# CC23x0 register map
File version: 1.1
CPU: CM0+ r0p4, little endian, no MPU, no FPU, VTOR, 3 interrupt priority bits
Registers are 32-bit, read-write, reset 0x0 unless marked. A register's access mark holds for its fields unless they carry their own. Offsets are from the block's base; [hi:lo] are bit positions; {n}, {i} and the like mark numbered series; 'fields as' and 'values as' point back to an identical list.

## IOC — ULL IOC
Base 0x40003000
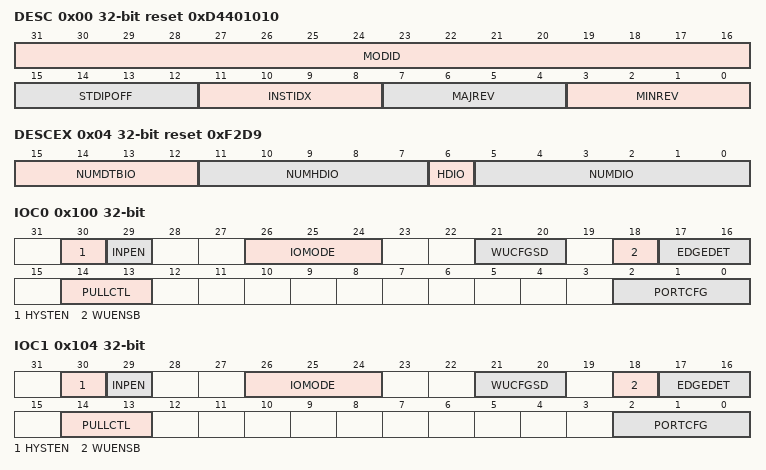
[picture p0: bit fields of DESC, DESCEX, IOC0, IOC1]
0x00 DESC ro reset 0xD4401010 — Description Register. This register provides IP module ID, revision information, instance index and standard MMR registers offset.
  [31:16] MODID — Module identifier used to uniquely identify this IP.
  [15:12] STDIPOFF — Standard IP MMR block offset. Standard IP MMRs are the set of from aggregated IRQ registers till DTB. 0: Standard IP MMRs do not exist 0x1-0xF: Standard IP MMRs begin at offset of (64*STDIPOFF from the base IP address)
  [11:8] INSTIDX — IP Instance ID number. If multiple instances of IP exist in the device, this field can identify the instance number (0-15).
  [7:4] MAJREV — Major revision of IP (0-15).
  [3:0] MINREV — Minor revision of IP (0-15).
0x04 DESCEX ro reset 0xF2D9 — Extended Description Register. This register provides configuration details of the IP to software drivers and end users.
  [15:12] NUMDTBIO — Number of DTB IOs supported. Total DTB IOs supported is NUMDTBIO value +1.
    15=MAXIMUM (Highest possible value); 0=MINIMUM (Smallest value)
  [11:7] NUMHDIO — Number of high drive IOs supported. Total high drive IOs supported is NUMHDIO value +1.
    31=MAXIMUM (Highest possible value); 0=MINIMUM (Smallest value)
  [6] HDIO — High drive IO supported by IOC.
    1=PRESENT (HD IO supported by IOC); 0=ABSENT (HD IO not supported by IOC)
  [5:0] NUMDIO — Number of DIOs supported. Total DIOs supported is NUMDIO value +1.
    63=MAXIMUM (Highest possible value); 0=MINIMUM (Smallest value)
0x100 IOC0 — Configuration of DIO0
  [30] HYSTEN — This field controls input hysteresis
    1=EN (Input hysteresis enabled); 0=DIS (Input hysteresis disabled)
  [29] INPEN — This field controls the input capability of DIO
    1=EN (Input enabled); 0=DIS (Input disabled)
  [26:24] IOMODE — IO Mode. Setting this to value 0x6 or 0x7 will default to normal IO behavior.
    5=OPENS_INV (Open Source, inverted IO); 4=OPENS (Open Source, normal IO); 3=OPEND_INV (Open Drain, inverted IO); 2=OPEND (Open Drain, normal IO); 1=INVERTED (Inverted IO); 0=NORMAL (Normal IO)
  [21:20] WUCFGSD — Wakeup configuration from shutdown
    3=WAKE_HIGH (Wakeup triggered when pad level is high); 2=WAKE_LOW (Wakeup triggered when pad level is low); 1=DIS_1 (Wakeup disabled); 0=DIS_0 (Wakeup disabled)
  [18] WUENSB — Wakeup enable from standby
    1=EN (Wakeup enabled (effective only if EDGEDET is enabled)); 0=DIS (Wakeup disabled)
  [17:16] EDGEDET — Edge detect configuration
    3=EDGE_BOTH (Positive and negative edge detection); 2=EDGE_POS (Positive edge detection); 1=EDGE_NEG (Negative edge detection); 0=EDGE_DIS (No edge detection)
  [14:13] PULLCTL — Pull control. Setting this to value 0x3 disables pull.
    2=PULL_UP (Pull up enabled); 1=PULL_DOWN (Pull down enabled); 0=PULL_DIS (No pull)
  [2:0] PORTCFG — Selects usage of DIO0
    7=DTB (Digital Test Bus function); 6=ANA (Analog function); {v}=PFUNC{v} (Digital peripheral function-{v}) (v=1..5); 0=BASE (Base function)
0x104 IOC1 — Configuration of DIO1
  [30] HYSTEN — This field controls input hysteresis
    values as IOC0.HYSTEN
  [29] INPEN — This field controls the input capability of DIO
    1=EN (Input enabled); 0=DIS (Input disabled)
  [26:24] IOMODE — IO Mode. Setting this to value 0x6 or 0x7 will default to normal IO behavior.
    values as IOC0.IOMODE
  [21:20] WUCFGSD — Wakeup configuration from shutdown
    values as IOC0.WUCFGSD
  [18] WUENSB — Wakeup enable from standby
    values as IOC0.WUENSB
  [17:16] EDGEDET — Edge detect configuration
    values as IOC0.EDGEDET
  [14:13] PULLCTL — Pull control. Setting this to value 0x3 disables pull.
    values as IOC0.PULLCTL
  [2:0] PORTCFG — Selects usage of DIO1
    values as IOC0.PORTCFG
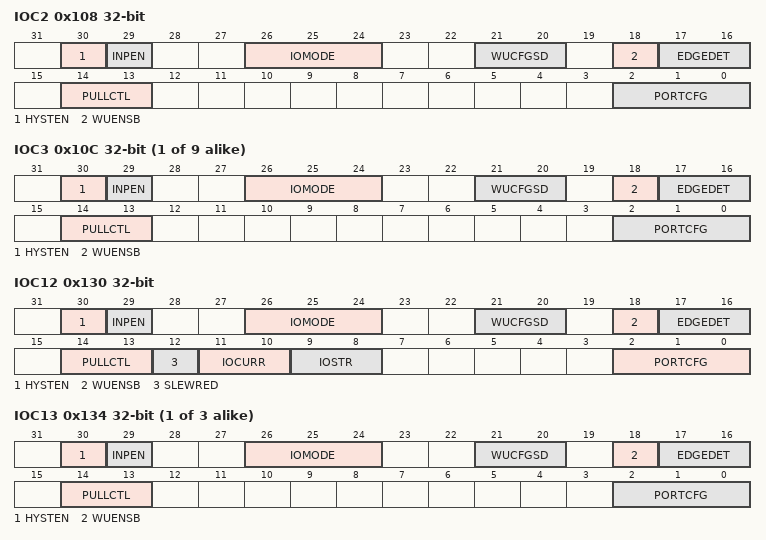
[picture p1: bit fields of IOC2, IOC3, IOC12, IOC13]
0x108 IOC2 — Selects usage of DIO2
  [30] HYSTEN — This field controls input hysteresis
    values as IOC0.HYSTEN
  [29] INPEN — This field controls the input capability of DIO
    1=EN (Input enabled); 0=DIS (Input disabled)
  [26:24] IOMODE — IO Mode. Setting this to value 0x6 or 0x7 will default to normal IO behavior.
    values as IOC0.IOMODE
  [21:20] WUCFGSD — Wakeup configuration from shutdown
    values as IOC0.WUCFGSD
  [18] WUENSB — Wakeup enable from standby
    values as IOC0.WUENSB
  [17:16] EDGEDET — Edge detect configuration
    values as IOC0.EDGEDET
  [14:13] PULLCTL — Pull control. Setting this to value 0x3 disables pull.
    values as IOC0.PULLCTL
  [2:0] PORTCFG — Selects usage of DIO2
    values as IOC0.PORTCFG
{0x100+4i} IOC{i} (i=3..11) — Configuration of DIO{i}
  [30] HYSTEN — This field controls input hysteresis
    values as IOC0.HYSTEN
  [29] INPEN — This field controls the input capability of DIO
    1=EN (Input enabled); 0=DIS (Input disabled)
  [26:24] IOMODE — IO Mode. Setting this to value 0x6 or 0x7 will default to normal IO behavior.
    values as IOC0.IOMODE
  [21:20] WUCFGSD — Wakeup configuration from shutdown
    values as IOC0.WUCFGSD
  [18] WUENSB — Wakeup enable from standby
    values as IOC0.WUENSB
  [17:16] EDGEDET — Edge detect configuration
    values as IOC0.EDGEDET
  [14:13] PULLCTL — Pull control. Setting this to value 0x3 disables pull.
    values as IOC0.PULLCTL
  [2:0] PORTCFG — Selects usage of DIO{i}
    values as IOC0.PORTCFG
0x130 IOC12 — Configuration of DIO12
  [30] HYSTEN — This field controls input hysteresis
    values as IOC0.HYSTEN
  [29] INPEN — This field controls the input capability of DIO
    1=EN (Input enabled); 0=DIS (Input disabled)
  [26:24] IOMODE — IO Mode. Setting this to value 0x6 or 0x7 will default to normal IO behavior.
    values as IOC0.IOMODE
  [21:20] WUCFGSD — Wakeup configuration from shutdown
    values as IOC0.WUCFGSD
  [18] WUENSB — Wakeup enable from standby
    values as IOC0.WUENSB
  [17:16] EDGEDET — Edge detect configuration
    values as IOC0.EDGEDET
  [14:13] PULLCTL — Pull control. Setting this to value 0x3 disables pull.
    values as IOC0.PULLCTL
  [12] SLEWRED — Slew rate configuration
    1=REDUCED (Reduced slew rate); 0=NORMAL (Normal slew rate)
  [11:10] IOCURR — Output current configuration. Writing value 0x3 defaults to 2mA current setting.
    2=CUR_8MA (8mA); 1=CUR_4MA (4mA); 0=CUR_2MA (2mA)
  [9:8] IOSTR — Drive strength configuration
    3=MAX (Maximum drive strength); 2=MEDIUM (Medium drive strength); 1=MIN (Minimum drive stregnth); 0=AUTO (Automatic drive strength adjustment)
  [2:0] PORTCFG — Selects usage of DIO12
    values as IOC0.PORTCFG
{0x100+4i} IOC{i} (i=13..15) — Configuration of DIO{i}
  fields as IOC3
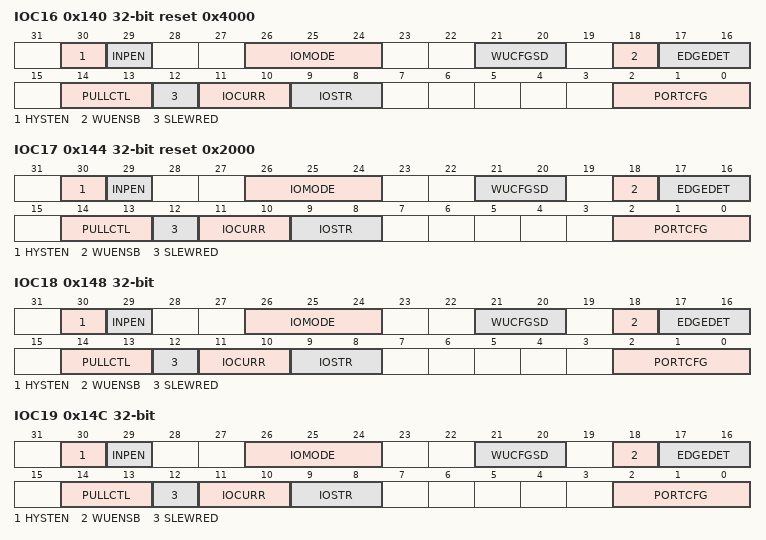
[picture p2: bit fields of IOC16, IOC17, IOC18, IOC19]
0x140 IOC16 reset 0x4000 — Configuration of DIO16
  [30] HYSTEN — This field controls input hysteresis
    values as IOC0.HYSTEN
  [29] INPEN — This field controls the input capability of DIO
    1=EN (Input enabled); 0=DIS (Input disabled)
  [26:24] IOMODE — IO Mode. Setting this to value 0x6 or 0x7 will default to normal IO behavior.
    values as IOC0.IOMODE
  [21:20] WUCFGSD — Wakeup configuration from shutdown
    values as IOC0.WUCFGSD
  [18] WUENSB — Wakeup enable from standby
    values as IOC0.WUENSB
  [17:16] EDGEDET — Edge detect configuration
    values as IOC0.EDGEDET
  [14:13] PULLCTL — Pull control. Setting this to value 0x3 disables pull.
    values as IOC0.PULLCTL
  [12] SLEWRED — Slew rate configuration
    1=REDUCED (Reduced slew rate); 0=NORMAL (Normal slew rate)
  [11:10] IOCURR — Output current configuration. Writing value 0x3 defaults to 2mA current setting.
    2=CUR_8MA (8mA); 1=CUR_4MA (4mA); 0=CUR_2MA (2mA)
  [9:8] IOSTR — Drive strength configuration
    values as IOC12.IOSTR
  [2:0] PORTCFG — Selects usage of DIO16
    values as IOC0.PORTCFG
0x144 IOC17 reset 0x2000 — Configuration of DIO17
  [30] HYSTEN — This field controls input hysteresis
    values as IOC0.HYSTEN
  [29] INPEN — This field controls the input capability of DIO
    1=EN (Input enabled); 0=DIS (Input disabled)
  [26:24] IOMODE — IO Mode. Setting this to value 0x6 or 0x7 will default to normal IO behavior.
    values as IOC0.IOMODE
  [21:20] WUCFGSD — Wakeup configuration from shutdown
    values as IOC0.WUCFGSD
  [18] WUENSB — Wakeup enable from standby
    values as IOC0.WUENSB
  [17:16] EDGEDET — Edge detect configuration
    values as IOC0.EDGEDET
  [14:13] PULLCTL — Pull control. Setting this to value 0x3 disables pull.
    values as IOC0.PULLCTL
  [12] SLEWRED — Slew rate configuration
    1=REDUCED (Reduced slew rate); 0=NORMAL (Normal slew rate)
  [11:10] IOCURR — Output current configuration. Writing value 0x3 defaults to 2mA current setting.
    2=CUR_8MA (8mA); 1=CUR_4MA (4mA); 0=CUR_2MA (2mA)
  [9:8] IOSTR — Drive strength configuration
    values as IOC12.IOSTR
  [2:0] PORTCFG — Selects usage of DIO17
    values as IOC0.PORTCFG
0x148 IOC18 — Configuration of DIO18
  [30] HYSTEN — This field controls input hysteresis
    values as IOC0.HYSTEN
  [29] INPEN — This field controls the input capability of DIO
    1=EN (Input enabled); 0=DIS (Input disabled)
  [26:24] IOMODE — IO Mode. Setting this to value 0x6 or 0x7 will default to normal IO behavior.
    values as IOC0.IOMODE
  [21:20] WUCFGSD — Wakeup configuration from shutdown
    values as IOC0.WUCFGSD
  [18] WUENSB — Wakeup enable from standby
    values as IOC0.WUENSB
  [17:16] EDGEDET — Edge detect configuration
    values as IOC0.EDGEDET
  [14:13] PULLCTL — Pull control. Setting this to value 0x3 disables pull.
    values as IOC0.PULLCTL
  [12] SLEWRED — Slew rate configuration
    1=REDUCED (Reduced slew rate); 0=NORMAL (Normal slew rate)
  [11:10] IOCURR — Output current configuration. Writing value 0x3 defaults to 2mA current setting.
    2=CUR_8MA (8mA); 1=CUR_4MA (4mA); 0=CUR_2MA (2mA)
  [9:8] IOSTR — Drive strength configuration
    values as IOC12.IOSTR
  [2:0] PORTCFG — Selects usage of DIO18
    values as IOC0.PORTCFG
0x14C IOC19 — Configuration of DIO19
  [30] HYSTEN — This field controls input hysteresis
    values as IOC0.HYSTEN
  [29] INPEN — This field controls the input capability of DIO
    1=EN (Input enabled); 0=DIS (Input disabled)
  [26:24] IOMODE — IO Mode. Setting this to value 0x6 or 0x7 will default to normal IO behavior.
    values as IOC0.IOMODE
  [21:20] WUCFGSD — Wakeup configuration from shutdown
    values as IOC0.WUCFGSD
  [18] WUENSB — Wakeup enable from standby
    values as IOC0.WUENSB
  [17:16] EDGEDET — Edge detect configuration
    values as IOC0.EDGEDET
  [14:13] PULLCTL — Pull control. Setting this to value 0x3 disables pull.
    values as IOC0.PULLCTL
  [12] SLEWRED — Slew rate configuration
    1=REDUCED (Reduced slew rate); 0=NORMAL (Normal slew rate)
  [11:10] IOCURR — Output current configuration. Writing value 0x3 defaults to 2mA current setting.
    2=CUR_8MA (8mA); 1=CUR_4MA (4mA); 0=CUR_2MA (2mA)
  [9:8] IOSTR — Drive strength configuration
    values as IOC12.IOSTR
  [2:0] PORTCFG — Selects usage of DIO19
    values as IOC0.PORTCFG
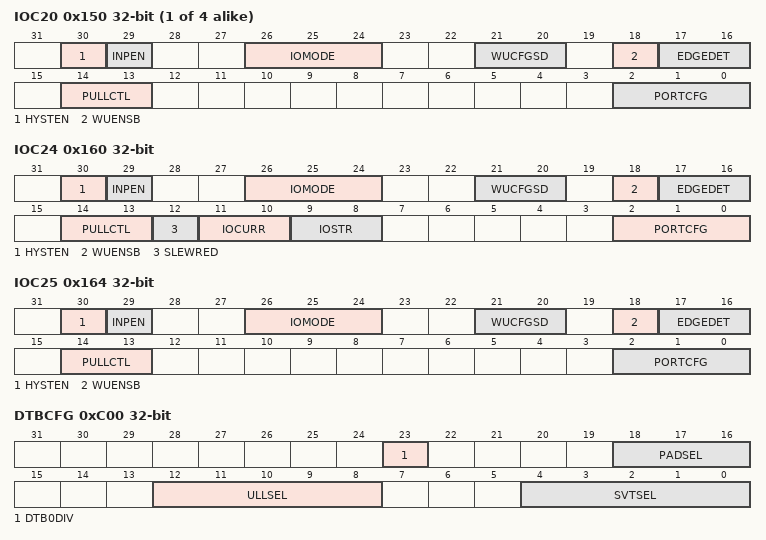
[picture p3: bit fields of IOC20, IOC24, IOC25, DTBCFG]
{0x100+4i} IOC{i} (i=20..23) — Configuration of DIO{i}
  fields as IOC3
0x160 IOC24 — Configuration of DIO24
  [30] HYSTEN — This field controls input hysteresis
    values as IOC0.HYSTEN
  [29] INPEN — This field controls the input capability of DIO
    1=EN (Input enabled); 0=DIS (Input disabled)
  [26:24] IOMODE — IO Mode. Setting this to value 0x6 or 0x7 will default to normal IO behavior.
    values as IOC0.IOMODE
  [21:20] WUCFGSD — Wakeup configuration from shutdown
    values as IOC0.WUCFGSD
  [18] WUENSB — Wakeup enable from standby
    values as IOC0.WUENSB
  [17:16] EDGEDET — Edge detect configuration
    values as IOC0.EDGEDET
  [14:13] PULLCTL — Pull control. Setting this to value 0x3 disables pull.
    values as IOC0.PULLCTL
  [12] SLEWRED — Slew rate configuration
    1=REDUCED (Reduced slew rate); 0=NORMAL (Normal slew rate)
  [11:10] IOCURR — Output current configuration. Writing value 0x3 defaults to 2mA current setting.
    2=CUR_8MA (8mA); 1=CUR_4MA (4mA); 0=CUR_2MA (2mA)
  [9:8] IOSTR — Drive strength configuration
    values as IOC12.IOSTR
  [2:0] PORTCFG — Selects usage of DIO24
    values as IOC0.PORTCFG
0x164 IOC25 — Selects usage of DIO25
  [30] HYSTEN — This field controls input hysteresis
    values as IOC0.HYSTEN
  [29] INPEN — This field controls the input capability of DIO
    1=EN (Input enabled); 0=DIS (Input disabled)
  [26:24] IOMODE — IO Mode. Setting this to value 0x6 or 0x7 will default to normal IO behavior.
    values as IOC0.IOMODE
  [21:20] WUCFGSD — Wakeup configuration from shutdown
    values as IOC0.WUCFGSD
  [18] WUENSB — Wakeup enable from standby
    values as IOC0.WUENSB
  [17:16] EDGEDET — Edge detect configuration
    values as IOC0.EDGEDET
  [14:13] PULLCTL — Pull control. Setting this to value 0x3 disables pull.
    values as IOC0.PULLCTL
  [2:0] PORTCFG — Selects usage of DIO25
    values as IOC0.PORTCFG
0xC00 DTBCFG — DTB configuration
  [23] DTB0DIV — This bit is used to divide DTB[0] output by 8.
    1=EN (Divide DTB[0] output by 8); 0=DIS (No divide)
  [18:16] PADSEL — Selects which 3 DTB lines out of total 16 are routed to DTB pins 15 to 13.
    5=DTB2TO0 (DTB[2:0] selected); 4=DTB5TO3 (DTB[5:3] selected); 3=DTB8TO6 (DTB[8:6] selected); 2=DTB11TO9 (DTB[11:9] selected); 1=DTB14TO12 (DTB[14:12] selected); 0=DTB15TO13 (DTB[15:13] selected)
  [12:8] ULLSEL — ULL DTB Mux selection
  [4:0] SVTSEL — SVT DTB Mux selection
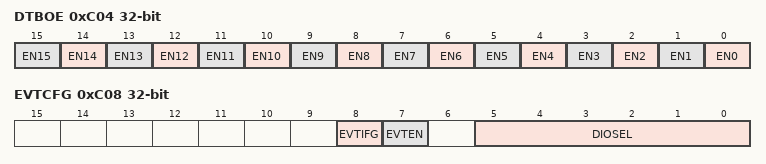
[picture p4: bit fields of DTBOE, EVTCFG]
0xC04 DTBOE — DTB output enable
  [all] fields
    1=EN (DTB output enabled); 0=DIS (DTB output disabled)
  [n] EN{n} (n=0..15) — Enables DTB output {n}
0xC08 EVTCFG — Event configuration. This register is used to select DIO for IOC to publish event on ULL event fabric. It also contains enable bit that is used to mask the event and event flag bit.
  [8] EVTIFG — Event flag. It is set when edge is detected on selected DIO. Note: The edge detector flop is cleared for the selected DIO when EVTIFG is cleared by software.
    1=SET (Set ULL event); 0=CLR (Clear ULL event)
  [7] EVTEN — Enables IOC to publish event on AON event fabric when EVTIFG is set.
    1=EN (Enable); 0=DIS (Disable)
  [5:0] DIOSEL — This is used to select DIO for event generation. For example, DIOSEL = 0x0 selects DIO0 and DIOSEL = 0x8 selects DIO8.
0xC0C TEST
  [0] SEL — This is used to drive SWDIO (Serial Wire DIO) output data and output enable from debug sub-system onto DIO12 (Test Data Output) pad.
    1=HI (Output data and output enable driven based on debug sub-system inputs); 0=LO (Output data and output enable managed by IOC)
0xC10 DTBSTAT ro — DTB status register.
  [15:0] VAL — This bit field captures the final 16-bit value of DTB signals provided from IOC to device pins.
